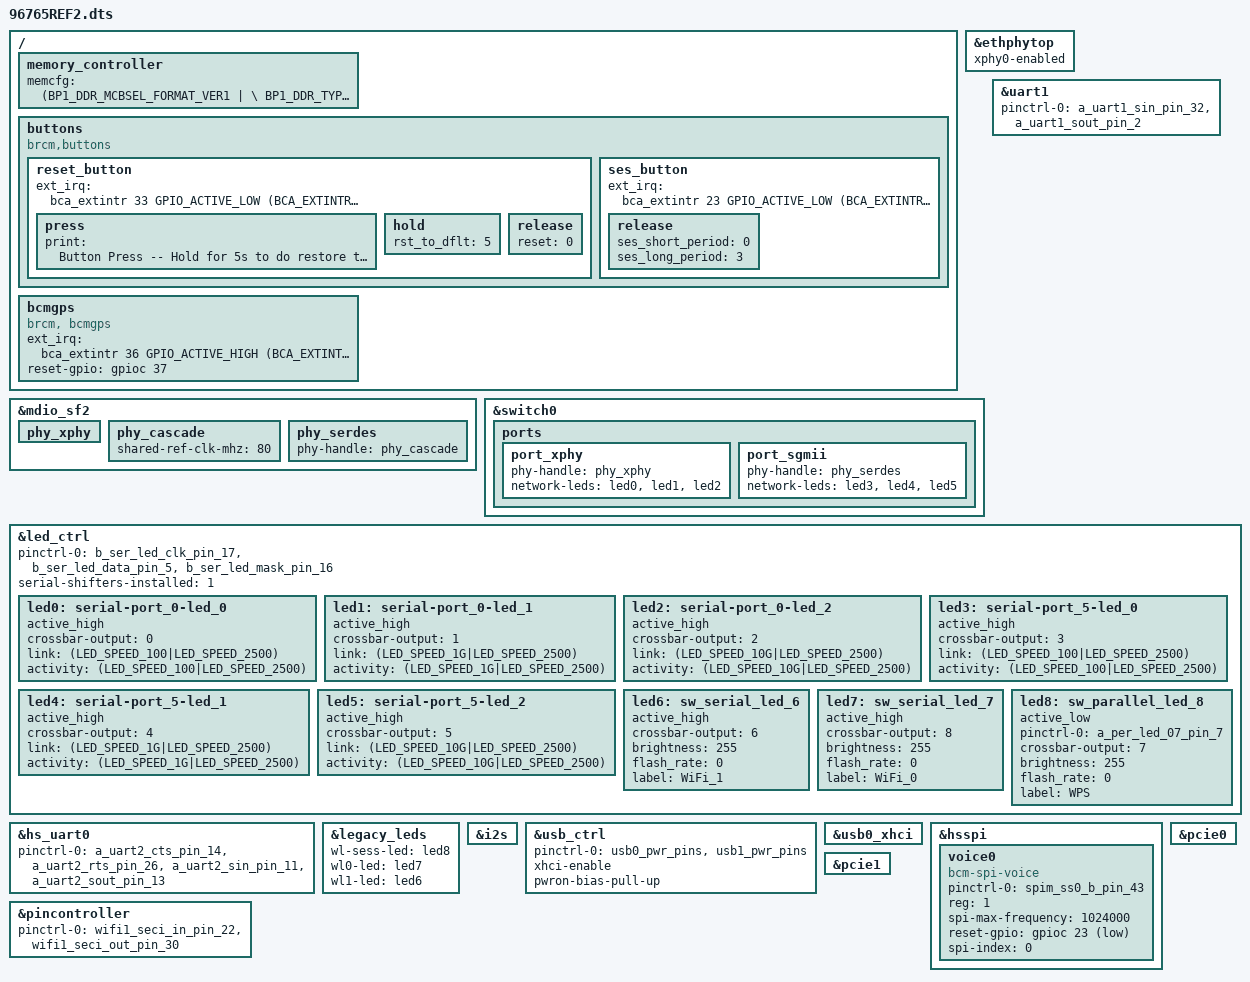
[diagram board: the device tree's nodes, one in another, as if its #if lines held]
#include "6765.dtsi"

/ {

	memory_controller {
		memcfg = <(BP1_DDR_MCBSEL_FORMAT_VER1 | \
			BP1_DDR_TYPE_LPDDR4               | \
			BP1_DDR_SPEED_2133_36_39_39       | \
			BP1_DDR_TOTAL_SIZE_8Gb            | \
			BP1_DDR_WIDTH_16BIT               | \
			BP1_DDR_6765_DEFAULT              | \
			BP1_DDR_CONFIG_DEBUG)>;
	};
	buttons {
		compatible = "brcm,buttons";
		reset_button {
			ext_irq = <&bca_extintr 33 GPIO_ACTIVE_LOW (BCA_EXTINTR_TYPE_LOW_LEVEL | BCA_EXTINTR_TYPE_SENSE_EDGE)>;
			press {
				print = "Button Press -- Hold for 5s to do restore to default";
			};
			hold {
				rst_to_dflt = <5>;
			};
			release {
				reset = <0>;
			};  
		};
		ses_button {
			ext_irq = <&bca_extintr 23 GPIO_ACTIVE_LOW (BCA_EXTINTR_TYPE_LOW_LEVEL | BCA_EXTINTR_TYPE_SENSE_EDGE)>;
			release {
				ses_short_period = <0>;
				ses_long_period = <3>;
			};
		};
	};
	bcmgps: bcmgps {
		compatible = "brcm, bcmgps"; 
		ext_irq = <&bca_extintr 36 GPIO_ACTIVE_HIGH (BCA_EXTINTR_TYPE_HIGH_LEVEL | BCA_EXTINTR_TYPE_SENSE_EDGE)>;   /* host_req */
		reset-gpio = <&gpioc 37 GPIO_ACTIVE_HIGH>;  /* nStandby */
		status = "okay";
	};
};


&mdio_sf2 {
       /* Port PHY mapping:
            port_imp -8#0- port_xhy <----> phy_xphy
                      # #
                      ##5- port_sgmii <-> phy_serdes - phy_cascade
         */
	phy_xphy {
		status = "okay";
	};
	phy_cascade {
	        shared-ref-clk-mhz = <80>;
		status = "okay";
	};
	phy_serdes {
		phy-handle = <&phy_cascade>;
		status = "okay";
	};
};

&ethphytop {
    xphy0-enabled;
    status = "okay";
};

&switch0 {

	ports {
		port_xphy {
			phy-handle = <&phy_xphy>;
			network-leds=<&led0 &led1 &led2>;
			status = "okay";
		};
		port_sgmii {
			phy-handle = <&phy_serdes>;
			network-leds=<&led3 &led4 &led5>;
			status = "okay";
		};
	};
};

&uart1 {
    pinctrl-names = "default";
    pinctrl-0 = <&a_uart1_sin_pin_32 &a_uart1_sout_pin_2>;
    status = "okay";
};

&led_ctrl {
	pinctrl-names = "default";
	pinctrl-0 = <&b_ser_led_clk_pin_17 &b_ser_led_data_pin_5 &b_ser_led_mask_pin_16>;
	serial-shifters-installed = <1>;

	led0: serial-port_0-led_0 {
		active_high;
		crossbar-output = <0>;
		link = <(LED_SPEED_100|LED_SPEED_2500)>;
		activity = <(LED_SPEED_100|LED_SPEED_2500)>;
		status = "okay";
	};
	led1: serial-port_0-led_1 {
		active_high;
		crossbar-output = <1>;
		link = <(LED_SPEED_1G|LED_SPEED_2500)>;
		activity = <(LED_SPEED_1G|LED_SPEED_2500)>;
		status = "okay";
	};
	led2: serial-port_0-led_2 {
		active_high;
		crossbar-output = <2>;
		link = <(LED_SPEED_10G|LED_SPEED_2500)>;
		activity = <(LED_SPEED_10G|LED_SPEED_2500)>;
		status = "okay";
	};
	led3: serial-port_5-led_0 {
		active_high;
		crossbar-output = <3>;
		link = <(LED_SPEED_100|LED_SPEED_2500)>;
		activity = <(LED_SPEED_100|LED_SPEED_2500)>;
		status = "okay";
	};
	led4: serial-port_5-led_1 {
		active_high;
		crossbar-output = <4>;
		link = <(LED_SPEED_1G|LED_SPEED_2500)>;
		activity = <(LED_SPEED_1G|LED_SPEED_2500)>;
		status = "okay";
	};
	led5: serial-port_5-led_2 {
		active_high;
		crossbar-output = <5>;
		link = <(LED_SPEED_10G|LED_SPEED_2500)>;
		activity = <(LED_SPEED_10G|LED_SPEED_2500)>;
		status = "okay";
	};
	led6: sw_serial_led_6 {
		active_high;
		crossbar-output = <6>;
		brightness = <255>;
		flash_rate = <0>;
		status = "okay";
		label = "WiFi_1";
	};
	led7: sw_serial_led_7 {
		active_high;
		crossbar-output = <8>;
		brightness = <255>;
		flash_rate = <0>;
		status = "okay";
		label = "WiFi_0";
	};

	led8: sw_parallel_led_8 {
		active_low; 
		pinctrl-0 = <&a_per_led_07_pin_7>;
		crossbar-output = <7>;
		brightness = <255>;
		flash_rate = <0>;
		status = "okay";
		label = "WPS";
	};

};

&hs_uart0 {
	pinctrl-0 = <&a_uart2_cts_pin_14 &a_uart2_rts_pin_26 &a_uart2_sin_pin_11 &a_uart2_sout_pin_13>;
	pinctrl-names = "default";
	status = "okay";
};

&legacy_leds {
	wl-sess-led = <&led8>;
	wl0-led = <&led7>;
	wl1-led = <&led6>;
};

&i2s {
	status="okay";
};

&usb_ctrl {
	pinctrl-names="default";
	pinctrl-0 = <&usb0_pwr_pins &usb1_pwr_pins>;
	status = "okay";
	xhci-enable;
	pwron-bias-pull-up;
};

&usb0_xhci {
	status = "okay";
};

&hsspi {
	status = "okay";
	voice0 {
		pinctrl-0 = <&spim_ss0_b_pin_43>;
		pinctrl-names = "default";
		compatible = "bcm-spi-voice";
		reg = <1>; /* chip select 1 */
		spi-max-frequency = <1024000>;
		reset-gpio = <&gpioc 23 GPIO_ACTIVE_LOW>;
		spi-index = <0>;/* voice header index */
	};
};

/* 
 * For BT Coex 
 */
&pincontroller {
    pinctrl-names = "default";
    /* pinctrl-0 = <&wifi1_gci_gpio_0_pin_22 &wifi1_gci_gpio_2_pin_29 &wifi1_gci_gpio_1_pin_30>; */ /* 3-Wire */
    pinctrl-0 = <&wifi1_seci_in_pin_22 &wifi1_seci_out_pin_30>; /* SECI */
};

#if defined(CONFIG_BCM_PCIE_HCD) || defined(CONFIG_BCM_PCIE_HCD_MODULE)
/**********************************************************************/
/* GPIO: Add one define per GPIO (individual or shared) regulator     */
/*       - Skip if no GPIO regulators in use                          */
/**********************************************************************/
#define PCIE0_REG_GPIO    34   /* PCIE0_PWR_CTRL for vreg_pcie0 node */
#define PCIE1_REG_GPIO    20   /* PCIE1_PWR_CTRL for vreg_pcie1 node */

#include "../bcm_wlan_regulator.dtsi"

/**********************************************************************/
/* Shared: Add brcm,supply-names = "vreg-pcieX" for shared PCIe nodes */
/*         - Skip if not using shared GPIO regulators                 */
/**********************************************************************/

/**********************************************************************/
/* PCIe: Add status = "okay" for each PCIe slots of this boiard       */
/*       - Skip if this is a derivative board (already done in base)  */
/**********************************************************************/
&pcie0 {
	status = "okay";
};

&pcie1 {
	status = "okay";
};
#endif //#if defined(CONFIG_BCM_PCIE_HCD) || defined(CONFIG_BCM_PCIE_HCD_MODULE)
